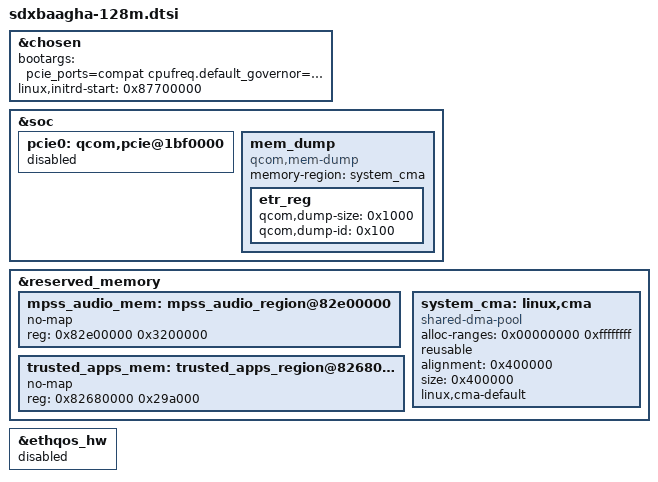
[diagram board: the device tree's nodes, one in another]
#include "sdxbaagha.dtsi"
/ {
};

&chosen {
	bootargs = "pcie_ports=compat cpufreq.default_governor=performance";
	linux,initrd-start = <0x87700000>;
};

&soc {
	pcie0: qcom,pcie@1bf0000 {
		status = "disabled";
	};
};

/delete-node/ &qcom_audio;
/delete-node/ &mpss_audio_mem;
/delete-node/ &audio_heap_mem;
/delete-node/ &system_cma;
/delete-node/ &trusted_apps_mem;
/delete-node/ &mem_dump;
&reserved_memory {
	mpss_audio_mem: mpss_audio_region@82e00000 {
		no-map;
		reg = <0x82e00000 0x3200000>;
	};

	trusted_apps_mem: trusted_apps_region@82680000 {
		no-map;
		reg = <0x82680000 0x29a000>;
	};

	system_cma: linux,cma {
		compatible = "shared-dma-pool";
		alloc-ranges = <0x00000000 0xffffffff>;
		reusable;
		alignment = <0x400000>;
		size = <0x400000>;
		linux,cma-default;
	};
};

&ethqos_hw {
	status = "disabled";
};

&soc {
	mem_dump {
		compatible = "qcom,mem-dump";
		memory-region = <&system_cma>;

		etr_reg {
			qcom,dump-size = <0x1000>;
			qcom,dump-id = <0x100>;
		};
	};
};
